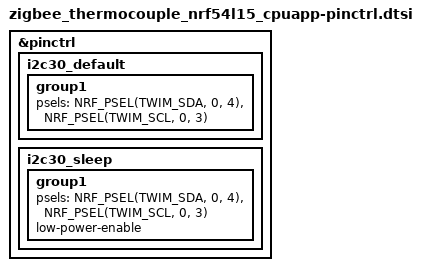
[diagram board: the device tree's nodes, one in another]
/*
 * Copyright (c) 2026 Daniel Kampert
 *
 * SPDX-License-Identifier: Apache-2.0
 */

&pinctrl {
    i2c30_default: i2c30_default {
        group1 {
            psels = <NRF_PSEL(TWIM_SDA, 0, 4)>,
                    <NRF_PSEL(TWIM_SCL, 0, 3)>;
        };
    };

    i2c30_sleep: i2c30_sleep {
        group1 {
            psels = <NRF_PSEL(TWIM_SDA, 0, 4)>,
                    <NRF_PSEL(TWIM_SCL, 0, 3)>;
            low-power-enable;
        };
    };
};
